# K210 register map
Vendor: Canaan Inc.; File version: 1.0
Registers are 32-bit, read-write, reset 0x0 unless marked. A register's access mark holds for its fields unless they carry their own. Offsets are from the block's base; [hi:lo] are bit positions; lines under a group give offsets from that group; {n}, {i} and the like mark numbered series.

## FPIOA — Field Programmable IO Array
Base 0x502B0000
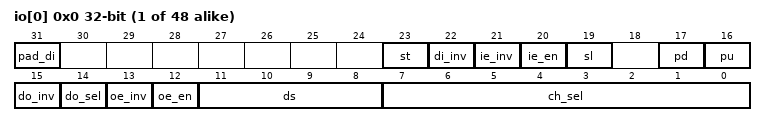
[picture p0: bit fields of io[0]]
{0x0+4i} io[{i}] (i=0..47) — FPIOA GPIO multiplexer io array
  [31] pad_di — Read current IO's data input
  [23] st — Schmitt trigger
  [22] di_inv — Invert Data input
  [21] ie_inv — Invert input enable
  [20] ie_en — Static input enable, will AND with IE_INV
  [19] sl — Slew rate control enable
  [17] pd — Pull down enable. 0 for nothing, 1 for pull down
  [16] pu — Pull up enable. 0 for nothing, 1 for pull up
  [15] do_inv — Invert the result of data output select (DO_SEL)
  [14] do_sel — Data output select: 0 for DO, 1 for OE
  [13] oe_inv — Invert output enable
  [12] oe_en — Static output enable, will AND with OE_INV
  [11:8] ds — Driving selector
  [7:0] ch_sel — Channel select from 256 input
{0xC0+4i} tie_en[{i}] (i=0..7) — FPIOA GPIO multiplexer tie enable array
{0xE0+4i} tie_val[{i}] (i=0..7) — FPIOA GPIO multiplexer tie value array

## SHA256 — SHA256 Accelerator
Base 0x502C0000
{0x0+4i} result[{i}] (i=0..7) — Calculated SHA256 return value
0x20 data_in — SHA256 input data is written to this register
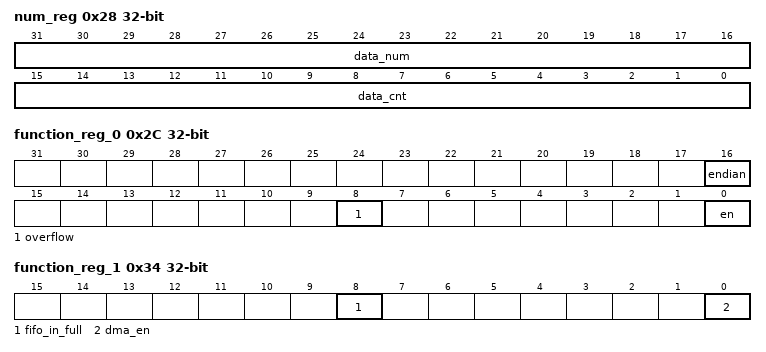
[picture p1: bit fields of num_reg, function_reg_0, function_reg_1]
0x28 num_reg — Counters register
  [31:16] data_num — Currently calculated block number. 512bit=1block
  [15:0] data_cnt — The total amount of data calculated by SHA256 is set by this register, and the smallest unit is 512bit
0x2C function_reg_0 — Function configuration register 0
  [16] endian — Endian setting
    0=le (Little endian); 1=be (Big endian)
  [8] overflow — SHA256 calculation overflow flag
  [0] en — write:SHA256 enable register. read:Calculation completed flag
0x34 function_reg_1 — Function configuration register 1
  [8] fifo_in_full — 1:SHA256 input fifo is full; 0:not full
  [0] dma_en — SHA and DMA handshake signals enable. 1:enable; 0:disable

## TIMER0
Base 0x502D0000
Same registers: TIMER1 0x502E0000, TIMER2 0x502F0000
{0x0+0x14*i} channel{i} (i=0..3) group — Channel cluster: load_count, current_value, control, eoi and intr_stat registers
  0x00 load_count
  0x04 current_value
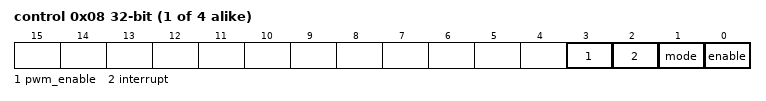
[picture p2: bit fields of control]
  0x08 control
    [3] pwm_enable
    [2] interrupt — INTERRUPT_MASK
    [1] mode
      0=FREE_MODE; 1=USER_MODE
    [0] enable
  0x0C eoi — Interrupt Clear Register
  0x10 intr_stat — Interrupt Status Register
0xA0 intr_stat — Interrupt Status Register
0xA4 eoi — Interrupt Clear Register
0xA8 raw_intr_stat — Raw Interrupt Status Register
0xAC comp_version — Component Version Register
{0xB0+4i} load_count2{i} (i=0..3)

## WDT0 — Watchdog Timer 0
Base 0x50400000
Same registers: WDT1 0x50410000
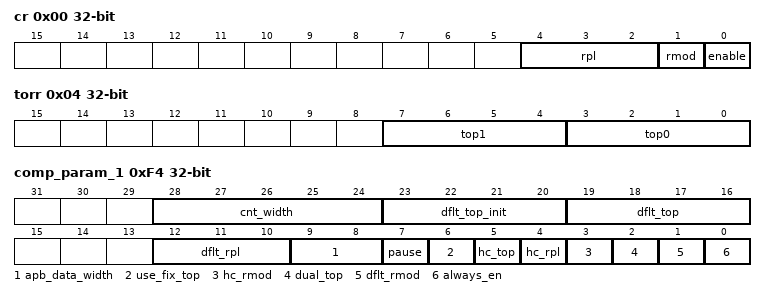
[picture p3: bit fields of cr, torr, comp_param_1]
0x00 cr — Control Register
  [4:2] rpl
  [1] rmod
    0=reset; 1=interrupt
  [0] enable
0x04 torr — Timeout Range Register
  [7:4] top1 — top (upper half)
  [3:0] top0 — top (lower half)
0x08 ccvr — Current Counter Value Register
0x0C crr — Counter Restart Register
0x10 stat — Interrupt Status Register
  [0] stat
0x14 eoi — Interrupt Clear Register
  [0] eoi
0x1C prot_level — Protection level Register
  [2:0] prot_level
0xE4 comp_param_5 — Component Parameters Register 5
  [31:0] user_top_max
0xE8 comp_param_4 — Component Parameters Register 4
  [31:0] user_top_init_max
0xEC comp_param_3 — Component Parameters Register 3
  [31:0] top_rst
0xF0 comp_param_2 — Component Parameters Register 2
  [31:0] cnt_rst
0xF4 comp_param_1 — Component Parameters Register 1
  [28:24] cnt_width, [23:20] dflt_top_init, [19:16] dflt_top, [12:10] dflt_rpl, [9:8] apb_data_width, [7] pause, [6] use_fix_top, [5] hc_top, [4] hc_rpl, [3] hc_rmod, [2] dual_top, [1] dflt_rmod, [0] always_en
0xF8 comp_version — Component Version Register
0xFC comp_type — Component Type Register

## DVP — Digital Video Port
Base 0x50430000
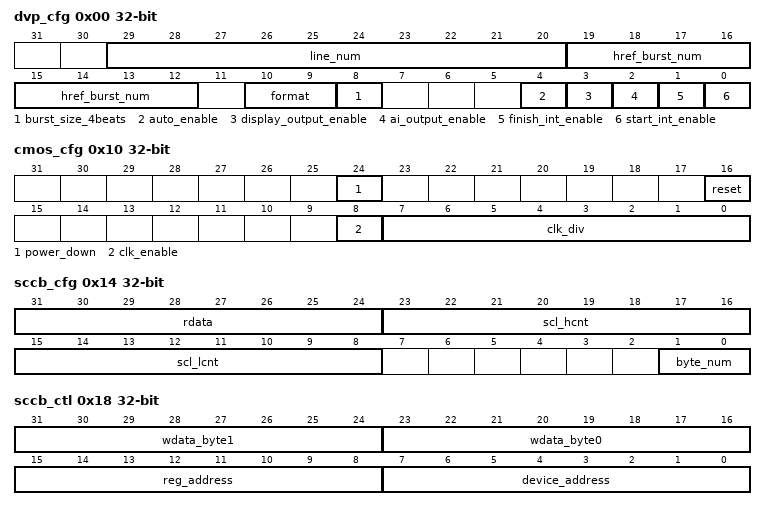
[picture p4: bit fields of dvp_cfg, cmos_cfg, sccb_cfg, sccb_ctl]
0x00 dvp_cfg — Config Register
  [29:20] line_num
  [19:12] href_burst_num
  [10:9] format
    0=rgb (RGB_FORMAT); 1=yuv (YUV_FORMAT); 3=y (Y_FORMAT)
  [8] burst_size_4beats
  [4] auto_enable
  [3] display_output_enable
  [2] ai_output_enable
  [1] finish_int_enable
  [0] start_int_enable
0x04 r_addr
0x08 g_addr
0x0C b_addr
0x10 cmos_cfg — CMOS Config Register
  [24] power_down, [16] reset, [8] clk_enable, [7:0] clk_div
0x14 sccb_cfg — SCCB Config Register
  [31:24] rdata ro
  [23:16] scl_hcnt
  [15:8] scl_lcnt
  [1:0] byte_num
    1=num2 (BYTE_NUM_2); 2=num3 (BYTE_NUM_3); 3=num4 (BYTE_NUM_4)
0x18 sccb_ctl — SCCB Control Register
  [31:24] wdata_byte1, [23:16] wdata_byte0, [15:8] reg_address, [7:0] device_address
0x1C axi
  [7:0] gm_mlen
    0=byte1 (GM_MLEN_1BYTE); 3=byte4 (GM_MLEN_4BYTE)
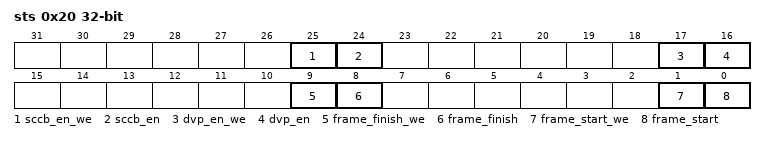
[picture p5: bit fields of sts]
0x20 sts
  [25] sccb_en_we, [24] sccb_en, [17] dvp_en_we, [16] dvp_en, [9] frame_finish_we, [8] frame_finish, [1] frame_start_we, [0] frame_start
0x24 reverse
0x28 rgb_addr
